# STM32WB05 register map
File version: 0.3
CPU: CM0+ r0p0, little endian, MPU, no FPU, 4 interrupt priority bits
Registers are 32-bit, read-write, reset 0x0 unless marked. A register's access mark holds for its fields unless they carry their own. Offsets are from the block's base; [hi:lo] are bit positions; {n}, {i} and the like mark numbered series; 'fields as' and 'values as' point back to an identical list; <NAME> marks a mode.

## PWRC
Base 0x48500000
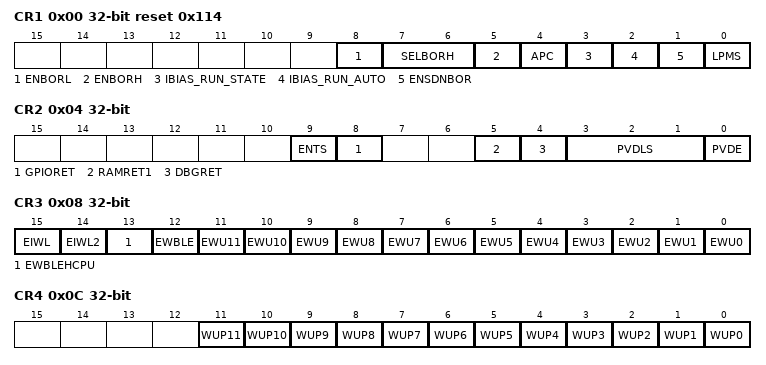
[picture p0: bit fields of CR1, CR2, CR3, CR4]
0x00 CR1 reset 0x114
  [8] ENBORL — ENBORL: Enable BORL reset supervising during RUN mode. 0: No BORL is monitored during RUN mode. 1: BORL is monitored during RUN mode (a POR reset will happen if VDDIO goes below 1.6V during RUN mode) (default). Note: Enabling this feature prevents blocking the device if VDDIO goes below supported voltages during RUN.
  [7:6] SELBORH — SELBORH[1:0]: BORH selection of Vbor threshold
    3=BORH Level 4(VBOR4): threshold level for above 2.81 V voltage operation; 2=BORH Level 3 (VBOR3): threshold level for above 2.52 V voltage operation; 1=BORH Level 2 (VBOR2): threshold level for above 2.21 V voltage operation; 0=BORH Level 1 (VBOR1): threshold level for above 2.0V voltage operation
  [5] ENBORH — ENBORH: enable BORH configuration
    1=BORH is enabled, threshold level depends on SELBOR[1:0]; 0=BORH off (VBOR0): threshold level for above 1.60V voltage operation
  [4] APC — APC Apply Pull-up and pull-down configuration from CPU
    1=the I/O pull-up and pull-down configurations defined in the PUCRx and PDCRx registers is applied; 0=the PUCRx and PDCRx are not used to control the I/O pull-up and pull-down configuration of the product I/Os
  [3] IBIAS_RUN_STATE — IBIAS_RUN_STATE: Enable/Disable IBIAS during RUN mode when automatic mode is disabled. 0: IBIAS control is disabled (default). 1: IBIAS control is enabled.
  [2] IBIAS_RUN_AUTO — IBIAS_RUN_AUTO: Enable automatic IBIAS control during RUN/DEEPSTOP mode. 0: IBIAS control is manual (and controlled by IBIAS_RUN_STATE register) 1: IBIAS control is automatic (default).
  [1] ENSDNBOR — ENSDNBOR: Enable BOR supply monitoring during shutdown mode.
    1=the PD_ALL_SHUTDOWN signal is not set during SHUTDOWN mode; 0=the PD_ALL_SHUTDOWN signal is set during SHUTDOWN mode
  [0] LPMS — LPMS Low Power Mode Selection Selection of the low power mode entered when CPU enters DEEP SLEEP mode and BLE is rdy2sleep.
    0=Deep Stop mode (default); 1=Shutdown mode
0x04 CR2
  [9] ENTS — ENTS: Enable Temperature Sensor
    1=Temperature sensor is enabled; 0=Temperature sensor is disabled
  [8] GPIORET — GPIORET: GPIO retention enable. 0: GPIO don't retain their status during DEEPSTOP and exiting from DEEPSTOP (default) 1: GPIO retain their status during DEEPSTOP and exiting from DEEPSTOP. Note: it's mandatory to ensure this bit is set before entering DEEPSTOP unless DBRG.DEEPSTOP2 bit is set.
  [5] RAMRET1 — RAMRET1: RAM1 retention during low power mode
    1=RAM1 bank is powered during low power mode; 0=RAM1 bank is disabled during low power mode (by default)
  [4] DBGRET — DBGRET: PA2 and PA3 retention enable after DEEPSTOP 0: PA2, PA3 don't retain their status exiting from DEEPSTOP. (default) 1: PA2, PA3 retain their status exiting from DEEPSTOP.
  [3:1] PVDLS — PVDLS[2:0] Programmable Voltage Detector Level selection then PVDO=1)
    0=2.05 V - Lowest level; 1=2.20 V; 2=2.36 V; 3=2.52 V; 4=2.64 V; 5=2.81 V; 6=2.91 V - Highest level; 7=External input analog voltage (compare internally to VBGP; When external input <VBGP
  [0] PVDE — PVDE Programmable Voltage Detector Enable When this bit is set the Power Voltage Detector is enabled
0x08 CR3
  [15] EIWL — EIWL: Enable wakeup on Internal event (RTC). 0: Wakeup on internal line is disabled (default). 1: Wakeup on internal line is enabled.
  [14] EIWL2 — EIWL2: Enable wakeup on Internal event (LPUART). 0: Wakeup on internal line is disabled (default). 1: Wakeup on internal line is enabled.
  [13] EWBLEHCPU — EWBLEHCPU: Enable wakeup on BLE Host CPU event. 0: Wakeup on BLE Host CPU line is disabled (default). 1: Wakeup on BLE Host CPU line is enabled.
  [12] EWBLE — EWBLE: Enable wakeup on BLE event. 0: Wakeup on BLE line is disabled (default). 1: Wakeup on BLE line is enabled.
  [n] EWU{n} (n=8..11) — EWU{n} Enable WakeUp line {n} (PA{n}) When this bit is set the wakeup line {n} is enabled and a rising or falling edge on wakeup line {n} will trigger a CPU wakeup event depending on CR4.WP{n} bit.
  [n] EWU{n} (n=0..7) — EWU{n} Enable WakeUp line {n} (PB{n}) When this bit is set the wakeup line {n} is enabled and a rising or falling edge on wakeup line {n} will trigger a CPU wakeup event depending on CR4.WP{n} bit.
0x0C CR4
  [all] fields
    0=Detection on high level (rising edge); 1=Detection on low level (falling edge)
  [n] WUP{n} (n=8..11) — WUP{n} Wake-up Line Polarity {n} (PA{n}) This bit defines the polarity used for event detection on external wake-up line {n}
  [n] WUP{n} (n=0..7) — WUP{n} Wake-up Line Polarity {n} (PB{n}) This bit defines the polarity used for event detection on external wake-up line {n}
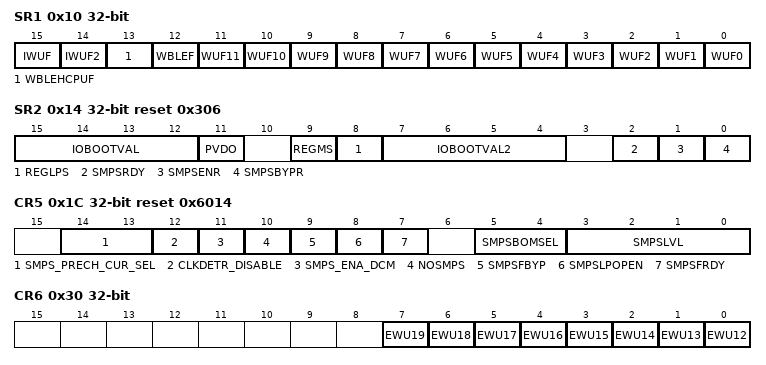
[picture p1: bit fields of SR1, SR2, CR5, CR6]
0x10 SR1
  [15] IWUF ro — IWUF: Internal wakeup flag (RTC). 0: no wakeup from RTC occurred since last clear. 1: a wakeup from RTC occurred since last clear. Note: The user must clear the RTC wakeup flag inside the RTC IP to clear this bit (mirror of the RTC wakeup line on the PWRC block).
  [14] IWUF2 ro — IWUF2: Internal wakeup 2 flag (LPUART). 0: no wakeup from LPUART occurred since last clear. 1: a wakeup from LPUART occurred since last clear. Note: The user must clear the LPUART wakeup flag inside the LPUART IP to clear this bit (mirror of the LPUART wakeup line on the PWRC block).
  [13] WBLEHCPUF — WBLEHCPUF: BLE Host CPU wakeup flag. 0: no wakeup from BLE Host CPU occurred since last clear. 1: a wakeup from BLE Host CPU occurred since last clear. Cleared by writing 1 in this bit.
  [12] WBLEF — WBLEF: BLE wakeup flag. 0: no wakeup from BLE occurred since last clear. 1: a wakeup from BLE occurred since last clear. Cleared by writing 1 in this bit.
  [n] WUF{n} (n=8..11) — WUF{n} WakeUp Flag {n} (PA{n}) This bit is set when a wakeup is detected on wakeup line {n}. It is cleared by a reset pad or by writing 1 in this bit field. writting this bit, clears the interrupt:
    0=no effect; 1=clear the interrupt
  [n] WUF{n} (n=0..7) — WUF{n} WakeUp Flag {n} (PB{n}) This bit is set when a wakeup is detected on wakeup line {n}. It is cleared by a reset pad or by writing 1 in this bit field. writting this bit, clears the interrupt:
    0=no effect; 1=clear the interrupt
0x14 SR2 ro reset 0x306
  [15:12] IOBOOTVAL — Bit3: PA11 input value on VDD33 latched at POR Bit2: PA10 input value on VDD33 latched at POR Bit1: PA9 input value on VDD33 latched at POR Bit0: PA8 input value on VDD33 latched at POR
  [11] PVDO — PVDO: Power Voltage Detector Output When the Power Voltage Detector is enabled (CR2.PVDE) this bit is set when the system supply (VDDIO) is lower than the selected PVD threshold (CR2.PVDLS)
  [9] REGMS — REGMS: Regulator Main LDO Started This bit provides the information whether main regulator is ready.
    0=Main regulator is not ready; 1=Main regulator is ready
  [8] REGLPS — REGLPS: Regulator Low Power Started This bit provides the information whether low power regulator is ready.
    0=LP regulator is not ready; 1=LP regulator is ready
  [7:4] IOBOOTVAL2 — Bit3: PB15 input value on VDD33 latched at POR Bit2: PB14 input value on VDD33 latched at POR Bit1: PB13 input value on VDD33 latched at POR Bit0: PB12 input value on VDD33 latched at POR
  [2] SMPSRDY — SMPSRDY: SMPS Ready Status This bit provides the information whether SMPS is ready.
    0=SMPS regulator is not ready; 1=SMPS regulator is ready
  [1] SMPSENR — SMPSENR: SMPS Enable Control Replica This bit mirrors the actual ENABLE_3V3 control signal driven to the SMPS regulator, dependant on the real working state.
  [0] SMPSBYPR — SMPSBYPR: SMPS Force Bypass Control Replica This bit mirrors the actual BYPASS_3V3 control signal driven to the SMPS regulator, dependant on the real working state.
0x1C CR5 reset 0x6014
  [14:13] SMPS_PRECH_CUR_SEL — SMPS_PRECH_CUR_SEL[1:0] Selection for SMPS PRECHARGE limit current
    0=2.5mA; 1=5mA; 2=10mA; 3=20mA (default)
  [12] CLKDETR_DISABLE — CLKDETR_DISABLE: disable SMPS clock detection The SMPS clock detection enables an automatic SMPS bypass switching in case of unwanted loss of SMPS clock.
    0=SMPS clock detection enabled (default); 1=SMPS clock detection disabled
  [11] SMPS_ENA_DCM — SMPS_ENA_DCM: enable discontinuous conduction mode
    0=disable; 1=enable
  [10] NOSMPS — NOSMPS: No SMPS Mode When this bit is set, the SMPS regulator will be disabled. Note that this configuration should be used only when SMPS_FB pad is directly connected to VBATT or Vext, without L/C BOM.
    0=No effect, SMPS is enabled; 1=SMPS is disabled;
  [9] SMPSFBYP — SMPSFB Force SMPS Regulator in bypass mode When this bit is set, the SMPS regulator will be forced to operate in precharge mode. the actual state of SMPS can be observed thanks to the replica SR2.SMPSBYPR.
    0=no effect (by default); 1=SMPS is disabled and bypassed (ENABLE_3V3=0 and PRECHARGE_3V3=1)
  [8] SMPSLPOPEN — SMPSLPOPEN: In Low Power mode SMPS is in OPEN mode (instead of PRECHARGE mode). When this bit is set, when the chip is in Low power mode the SMPS regulator will be disabled (HZ) Documentation needed.
    0=in Low Power mode, SMPS is in PRECHARGE, output is connected to VDDIO; 1=in Low Power mode, SMPS is disabled, output is floating
  [7] SMPSFRDY — SMPSFB Force ready check When this bit is set, the SMPS FSM will consider the SMPS ready .
    0=no effect (by default); 1=SMPS is considered READY
  [5:4] SMPSBOMSEL — SMPSBOMSEL: SMPS BOM Selection:
    0=BOM1; 1=BOM2 (default); 2=BOM3; 3=n/a
  [3:0] SMPSLVL — SMPSLVL[3:0] SMPS Output Level Voltage Selection Select the SMPS output voltage with a granularity of 50mV. Default = '0100' (1.4V) Vout = 1.2 + 0.05*SMPSOUT (V)
0x20 PUCRA reset 0xF07
  [15:0] PU — PU[x] : Pull Up Pull up activation on port A[i] pad when APC bit of PWRC CR3 is set
    1=Pull-Up activated on port A[i] when APC bit of PWRC CR3 bit is set and PWR_PDCRA[x] is reset; 0=Pull-Up not activated on port A[i]
0x24 PDCRA reset 0x8
  [15:0] PD — PD[x]: Pull Down Pull Down activation on port A[i] pad when APC bit of PWRC CR3 is set
    1=Pull-Down activated on Port A[i] when APC bit of PWRC CR3 bit is set; 0=Pull-Down not activated on Port A[i]
0x28 PUCRB reset 0xF0FF
  [15:0] PU — PU[x] : Pull Up Pull up activation on port B[i] pad when APC bit of PWRC CR3 is set
    1=Pull-Up activated on port B[i] when APC bit of PWRC CR3 bit is set and PWR_PDCRB[x] is reset; 0=Pull-Up not activated on port B[i]
0x2C PDCRB
  [15:0] PD — PD[x]: Pull Down Pull Down activation on port B[i] pad when APC bit of PWRC CR3 is set
    1=Pull-Down activated on Port B[i] when APC bit of PWRC CR3 bit is set; 0=Pull-Down not activated on Port B[i]
0x30 CR6
  [n-12] EWU{n} (n=16..19) — EWU{n} Enable WakeUp line {n} (PB{n-4}) When this bit is set the wakeup line {n} is enabled and a rising or falling edge on wakeup line {n-12} will trigger a CPU wakeup event depending on CR7.WP{n-12} bit.
  [n-12] EWU{n} (n=12..15) — EWU{n} Enable WakeUp line {n} (PA{n-12}) When this bit is set the wakeup line {n} is enabled and a rising or falling edge on wakeup line {n-12} will trigger a CPU wakeup event depending on CR7.WP{n-12} bit.
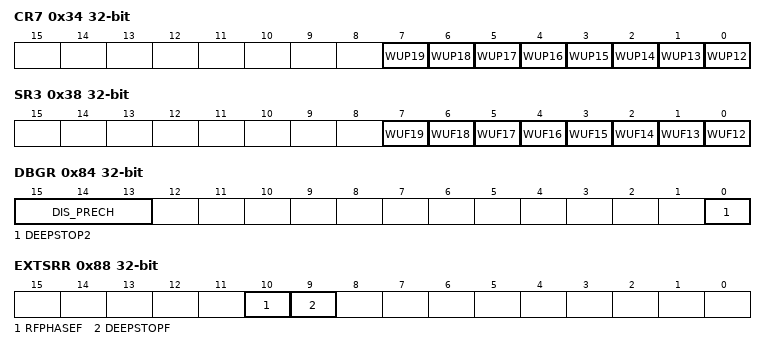
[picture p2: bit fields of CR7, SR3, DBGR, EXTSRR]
0x34 CR7
  [all] fields
    values as the fields of CR4
  [n-12] WUP{n} (n=16..19) — WUP{n} Wake-up Line Polarity {n} (PB{n-4}) This bit defines the polarity used for event detection on external wake-up line {n}
  [n-12] WUP{n} (n=12..15) — WUP{n} Wake-up Line Polarity {n} (PA{n-12}) This bit defines the polarity used for event detection on external wake-up line {n}
0x38 SR3
  [all] fields
    0=no effect; 1=clear the interrupt
  [n-12] WUF{n} (n=16..19) — WUF{n} WakeUp Flag {n} PB{n-4} This bit is set when a wakeup is detected on wakeup line {n}. It is cleared by a reset pad or by writing 1 in this bit field. writting this bit, clears the interrupt:
  [n-12] WUF{n} (n=12..15) — WUF{n} WakeUp Flag {n} PA{n-12} This bit is set when a wakeup is detected on wakeup line {n}. It is cleared by a reset pad or by writing 1 in this bit field. writting this bit, clears the interrupt:
0x84 DBGR
  [15:13] DIS_PRECH — DIS_PRECH[2:0]: disable precharge during deepstop (debug) - 111: precharge and SMPS monitoring are disabled (whatever CR5.SMPSLPOPEN) - 101: precharge are activated only at deepstop exit (to be used only with CR5.SMPSLPOPEN=1) - else: No effect (default 0x0)
  [0] DEEPSTOP2 — DEEPSTOP2: DEEPSTOP2 low power saving emulation enable. 0: normal DEEPSTOP will be applied 1: DEEPSTOP2 (debugger features not lost) will be applied instead of DEEPSTOP.
0x88 EXTSRR
  [10] RFPHASEF — RFPHASEF RFPHASE Flag This bit is set by hardware after a Radio wake-up event (BLE activation); it is cleared either by software, writing '1' in this bit field, or by hardware when Ready2Sleep signal is asserted by the Radio IP.
    0=RF IP does not require attention; 1=RF IP awake and requesting system attention
  [9] DEEPSTOPF — DEEPSTOPF System DeepStop Flag This bit is set by hardware and cleared only by a POR reset or by writing '1' in this bit field
    0=System has not been in DEEPSTOP mode; 1=System has been in DEEPSTOP mode
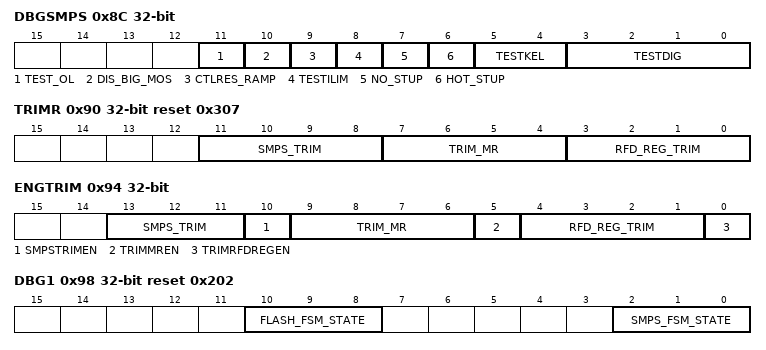
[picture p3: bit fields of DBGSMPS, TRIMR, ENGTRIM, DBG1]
0x8C DBGSMPS
  [11] TEST_OL — TEST_OL_3V3 SMPS control signal
  [10] DIS_BIG_MOS — DIS_BIG_MOS_3V3 SMPS control signal
  [9] CTLRES_RAMP — CTLRES_RAM_3V3 SMPS control signal
  [8] TESTILIM — TESTILIM: SMPS TEST_ILIM_3V3 SMPS control signal
  [7] NO_STUP — NO_STUP_3V3 SMPS control signal
  [6] HOT_STUP — HOT_STUP_3V3 SMPS control signal
  [5:4] TESTKEL — TESTKEL: SMPS TEST_KEL_3V3[1:0] SMPS control signal
  [3:0] TESTDIG — TESTDIG: SMPS TEST_DIG_3V3[3:0] SMPS control signal
0x90 TRIMR ro reset 0x307
  [11:8] SMPS_TRIM — SMPS_TRIM[2:0]: SMPS output voltage trimming. Note: the default value is the centered value ('011').
  [7:4] TRIM_MR — TRIM_MR[3:0]: Main regulator voltage trimming. Default value when no trimming is '0000'.
  [3:0] RFD_REG_TRIM — RFD_REG_TRIM[3:0]: RF LDO trimming. Default value when no trimming is '0111'.
0x94 ENGTRIM
  [13:11] SMPS_TRIM — SMPS_TRIM[2:0]: SMPS output voltage trimming chosen by the software.
  [10] SMPSTRIMEN — SMPSTRIMEN: SMPS_TRIM software overload enable. 0: Hardware trimming value from TRIMR.SMPS_TRIM bit field is applied. 1: Trimming value from ENGTRIM.SMPS_TRIM bit field is applied
  [9:6] TRIM_MR — TRIM_MR[3:0]: Main regulator voltage trimming chosen by the software.
  [5] TRIMMREN — TRIMMREN: TRIM_MR software overload enable. 0: Hardware trimming value from TRIMR.TRIM_MR bit field is applied. 1: Software trimming value from ENGTRIM.TRIM_MR bit field is applied
  [4:1] RFD_REG_TRIM — RFD_REG_TRIM[3:0]: RF LDO trimming chosen by the software.
  [0] TRIMRFDREGEN — TRIMRFDREGEN: RFD_REG_TRIM software overload enable. 0: Hardware trimming value from TRIMR.RFD_REG_TRIM bit field is applied. 1: Software trimming value from ENGTRIM.RFD_REG_TRIM bit field is applied
0x98 DBG1 ro reset 0x202
  [10:8] FLASH_FSM_STATE — These bits are set and cleared by the FLASH FSM.They show the sequencer executed states. 2: READY 3: SWITCH OFF 4: POWER DOWN
    0=POR; 1=POWER UP
  [2:0] SMPS_FSM_STATE — These bits are set and cleared by the SMPS FSM.They show the sequencer executed states. 2: SMPS RUN 3: STOP 4: NOSMPS 5: PRECHARGE
    0=STARTUP; 1=SMPS REQ
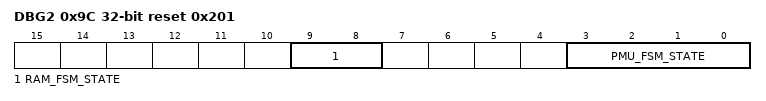
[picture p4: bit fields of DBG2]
0x9C DBG2 ro reset 0x201
  [9:8] RAM_FSM_STATE — These bits are set and cleared by the RAM FSM.They show the sequencer executed states. 2: READY 3: OFF
    0=POR; 1=POWER UP
  [3:0] PMU_FSM_STATE — These bits are set and cleared by the PMU FSM.They show the sequencer executed states. 2: DS ENTRY 3: WAIT1 4: WAIT2 5: WAIT 6: WAIT3 7: WAIT4 8: ISOLATION 9: DEEPSTOP
    0=POR; 1=RUN; 2=SHUTDOWN; 3=DEEPSTOP EXIT
